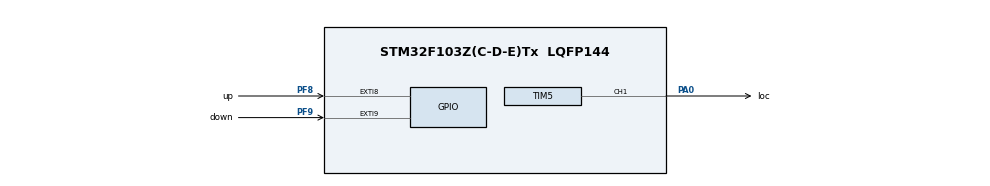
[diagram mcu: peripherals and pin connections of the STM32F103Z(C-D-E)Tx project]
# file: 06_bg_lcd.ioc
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Mcu.Family=STM32F1
Mcu.Name=STM32F103Z(C-D-E)Tx
Mcu.Package=LQFP144
NVIC.EXTI9_5_IRQn=true\:1\:0\:true\:false\:true\:true\:true\:true
NVIC.PriorityGroup=NVIC_PRIORITYGROUP_4
OSC_IN.Mode=HSE-External-Oscillator
OSC_IN.Signal=RCC_OSC_IN
OSC_OUT.Mode=HSE-External-Oscillator
OSC_OUT.Signal=RCC_OSC_OUT
PA0-WKUP.GPIO_Label=loc
PA0-WKUP.Signal=S_TIM5_CH1
PA13.Mode=Serial_Wire
PA13.Signal=SYS_JTMS-SWDIO
PA14.Mode=Serial_Wire
PA14.Signal=SYS_JTCK-SWCLK
PC14-OSC32_IN.Mode=LSE-External-Oscillator
PC14-OSC32_IN.Signal=RCC_OSC32_IN
PC15-OSC32_OUT.Mode=LSE-External-Oscillator
PC15-OSC32_OUT.Signal=RCC_OSC32_OUT
PF8.GPIO_Label=up
PF8.GPIO_ModeDefaultEXTI=GPIO_MODE_IT_FALLING
PF8.GPIO_PuPd=GPIO_PULLDOWN
PF8.Signal=GPXTI8
PF9.GPIO_Label=down
PF9.Signal=GPXTI9
ProjectManager.HeapSize=0x200
ProjectManager.StackSize=0x400
ProjectManager.TargetToolchain=CMake
RCC.APB1Freq_Value=8000000
RCC.APB2Freq_Value=8000000
SH.S_TIM5_CH1.0=TIM5_CH1,PWM Generation1 CH1
TIM5.Channel-PWM\ Generation1\ CH1=TIM_CHANNEL_1
board=custom

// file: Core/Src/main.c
/* USER CODE BEGIN Header */
/**
  ******************************************************************************
  * @file           : main.c
  * @brief          : Main program body
  ******************************************************************************
  * @attention
  *
  * Copyright (c) 2026 STMicroelectronics.
  * All rights reserved.
  *
  * This software is licensed under terms that can be found in the LICENSE file
  * in the root directory of this software component.
  * If no LICENSE file comes with this software, it is provided AS-IS.
  *
  ******************************************************************************
  */
/* USER CODE END Header */
#include "main.h"
#include "tim.h"
#include "gpio.h"

void SystemClock_Config(void);

/* USER CODE BEGIN 0 */

// PWM 占空比
volatile int duty = 50;

/* 按键事件标志 (0=无事件, 1=UP, 2=DOWN) */
volatile uint8_t key_event = 0;
/* 最近一次有效按键中断的时间戳 (用于非阻塞消抖) */
volatile uint32_t key_last_tick = 0;

/* 软消抖时间窗 (ms) */
#define DEBOUNCE_MS 20

/* USER CODE END 0 */

int main(void)
{

  /* MCU Configuration--------------------------------------------------------*/

  /* Reset of all peripherals, Initializes the Flash interface and the Systick. */
  HAL_Init();

  /* Configure the system clock */
  SystemClock_Config();

  /* Initialize all configured peripherals */
  MX_GPIO_Init();
  MX_TIM5_Init();
  /* USER CODE BEGIN 2 */

  // 开启TIM3
  HAL_TIM_PWM_Start(&htim5, TIM_CHANNEL_1);

  /* USER CODE END 2 */

  /* Infinite loop */
  while (1)
  {

    /* 处理按键事件：二次确认电平 + 边界保护 */
    if (key_event != 0)
    {
      uint8_t ev = key_event;
      key_event = 0;   // 取出后立刻清零

      if (ev == 1 && HAL_GPIO_ReadPin(up_GPIO_Port, up_Pin) == GPIO_PIN_SET)
      {
        duty = (duty + 10 > 100) ? 100 : duty + 10;
      }
      else if (ev == 2 && HAL_GPIO_ReadPin(down_GPIO_Port, down_Pin) == GPIO_PIN_SET)
      {
        duty = (duty - 10 < 1) ? 1 : duty - 10;
      }
    }

    /* 把最新占空比推到 TIM5 CH1 (LCD 背光 PWM) */
    set_pwm_duty(duty);

  }
}

void SystemClock_Config(void)
{
  RCC_OscInitTypeDef RCC_OscInitStruct = {0};
  RCC_ClkInitTypeDef RCC_ClkInitStruct = {0};

  /** Initializes the RCC Oscillators according to the specified parameters
  * in the RCC_OscInitTypeDef structure.
  */
  RCC_OscInitStruct.OscillatorType = RCC_OSCILLATORTYPE_HSI;
  RCC_OscInitStruct.HSIState = RCC_HSI_ON;
  RCC_OscInitStruct.HSICalibrationValue = RCC_HSICALIBRATION_DEFAULT;
  RCC_OscInitStruct.PLL.PLLState = RCC_PLL_NONE;
  if (HAL_RCC_OscConfig(&RCC_OscInitStruct) != HAL_OK)
  {
    Error_Handler();
  }

  /** Initializes the CPU, AHB and APB buses clocks
  */
  RCC_ClkInitStruct.ClockType = RCC_CLOCKTYPE_HCLK|RCC_CLOCKTYPE_SYSCLK
                              |RCC_CLOCKTYPE_PCLK1|RCC_CLOCKTYPE_PCLK2;
  RCC_ClkInitStruct.SYSCLKSource = RCC_SYSCLKSOURCE_HSI;
  RCC_ClkInitStruct.AHBCLKDivider = RCC_SYSCLK_DIV1;
  RCC_ClkInitStruct.APB1CLKDivider = RCC_HCLK_DIV1;
  RCC_ClkInitStruct.APB2CLKDivider = RCC_HCLK_DIV1;

  if (HAL_RCC_ClockConfig(&RCC_ClkInitStruct, FLASH_LATENCY_0) != HAL_OK)
  {
    Error_Handler();
  }
}

/* USER CODE BEGIN 4 */

// KEY按键中断回调函数 (非阻塞，仅记录事件)
void HAL_GPIO_EXTI_Callback(uint16_t GPIO_Pin)
{
  uint32_t now = HAL_GetTick();
  /* 软消抖：忽略 DEBOUNCE_MS 时间窗内的重复触发，避免机械抖动误判 */
  if ((now - key_last_tick) < DEBOUNCE_MS) return;
  key_last_tick = now;

  if (GPIO_Pin == up_Pin) key_event = 1;
  else if (GPIO_Pin == down_Pin) key_event = 2;
}

/* USER CODE END 4 */

void Error_Handler(void)
{
  __disable_irq();
  while (1)
  {
  }
}
